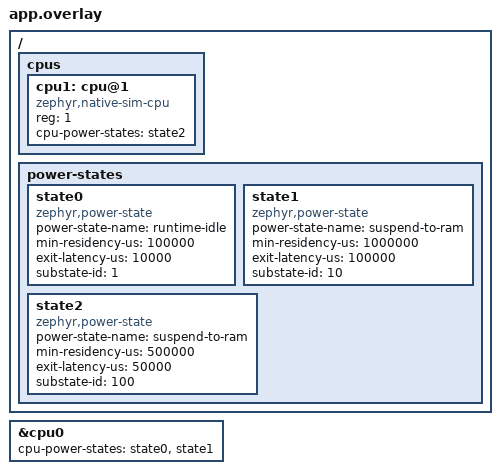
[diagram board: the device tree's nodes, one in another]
/*
 * Copyright (c) 2021 Nordic Semiconductor ASA
 * SPDX-License-Identifier: Apache-2.0
 */

/ {
	cpus {
		cpu1: cpu@1 {
			compatible = "zephyr,native-sim-cpu";
			reg = <1>;
			cpu-power-states = <&state2>;
		};
	};

	power-states {
		state0: state0 {
			compatible = "zephyr,power-state";
			power-state-name = "runtime-idle";
			min-residency-us = <100000>;
			exit-latency-us = <10000>;
			substate-id = <1>;
		};

		state1: state1 {
			compatible = "zephyr,power-state";
			power-state-name = "suspend-to-ram";
			min-residency-us = <1000000>;
			exit-latency-us = <100000>;
			substate-id = <10>;
		};

		state2: state2 {
			compatible = "zephyr,power-state";
			power-state-name = "suspend-to-ram";
			min-residency-us = <500000>;
			exit-latency-us = <50000>;
			substate-id = <100>;
		};
	};
};

&cpu0 {
	cpu-power-states = <&state0 &state1>;
};
